# MINI51XAE_v1 register map
File version: 1.0
MINI51XAE_v1 SVD file
Registers are 32-bit, read-write, reset 0x0 unless marked. A register's access mark holds for its fields unless they carry their own. Offsets are from the block's base; lines under a group give offsets from that group; [hi:lo] are bit positions; {n}, {i} and the like mark numbered series; 'fields as' and 'values as' point back to an identical list; <NAME> marks a mode.

## Memory map
0x40004000 WDT size 0x4 — WDT Register Map
0x40010000 TMR blocks up to offset 0x50 — TMR Register Map
0x40020000 I2C blocks up to offset 0x44 — I2C Register Map
0x40030000 SPI blocks up to offset 0x48 — SPI Register Map
0x40040000 PWM blocks up to offset 0x88 — PWM Register Map
0x40050000 UART0 size 0x34 — UART Register Map
0x400D0000 ACMP size 0x10 — ACMP Register Map
0x400E0000 ADC blocks up to offset 0x58 — ADC Register Map
0x40150000 UART1 size 0x34 — UART Register Map
0x50000000 SYS blocks up to offset 0x104 — SYS Register Map
0x50000200 CLK blocks up to offset 0x28 — CLK Register Map
0x50000300 INT blocks up to offset 0x88 — INT Register Map
0x50004000 GP blocks up to offset 0x2B8 — GPIO Register Map
0x5000C000 FMC blocks up to offset 0x44 — FMC Register Map
0x50014000 HDIV size 0x14 — HDIV Register Map
0xE000E000 SCS blocks up to offset 0xD24 — SCS Register Map

## INT — INT Register Map
Base 0x50000300
{0x0+4i} IRQ{i}SRC ro reset not defined (i=0..9) — IRQ{i} (BOD) Interrupt Source Identity
  [2:0] INT_SRC — Interrupt Source
{0x0+4i} IRQ{i}SRC ro reset not defined (i=12..14) — IRQ{i} (BOD) Interrupt Source Identity
  [2:0] INT_SRC — Interrupt Source
{0x0+4i} IRQ{i}SRC ro reset not defined (i=16..18) — IRQ{i} (BOD) Interrupt Source Identity
  [2:0] INT_SRC — Interrupt Source
0x64 IRQ25SRC ro reset not defined — IRQ25 (BOD) Interrupt Source Identity
  [2:0] INT_SRC — Interrupt Source
0x70 IRQ28SRC ro reset not defined — IRQ28 (BOD) Interrupt Source Identity
  [2:0] INT_SRC — Interrupt Source
0x74 IRQ29SRC ro reset not defined — IRQ29 (BOD) Interrupt Source Identity
  [2:0] INT_SRC — Interrupt Source
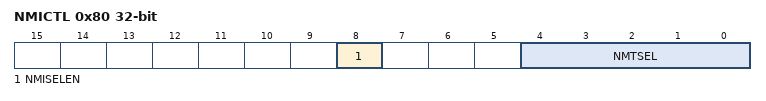
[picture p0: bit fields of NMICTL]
0x80 NMICTL — NMI Source Interrupt Select Control Register
  [8] NMISELEN — NMI Interrupt Enable Control (Write Protected). Note: This bit is the protected bit, and programming it needs to write 0x59, 0x16, and 0x88 to address 0x5000_0100 to disable register protection. Refer to the register REGWRPROT at address SYS_BA+0x100.
    0=NMI interrupt Disabled; 1=NMI interrupt Enabled
  [4:0] NMTSEL — NMI Interrupt Source Selection. The NMI interrupt to Cortex-M0 can be selected from one of the peripheral interrupt by setting NMTSEL.
0x84 IRQSTS — MCU IRQ Number Identity Register
  [31:0] IRQ — MCU IRQ Source Register. The IRQ collects all the interrupts from the peripherals and generates the synchronous interrupt to Cortex-M0 core. There are two modes to generate interrupt to Cortex-M0 - the normal mode and test mode. The IRQ collects all interrupts from each peripheral and synchronizes them then interrupts the Cortex-M0. When the IRQ[n] is 0, setting IRQ[n] to 1 will generate an interrupt to Cortex-M0 NVIC[n]. When the IRQ[n] is 1 (mean an interrupt is assert), setting 1 to the MCU_bit[n] will clear the interrupt and setting IRQ[n] 0 has no effect.

## HDIV — HDIV Register Map
Base 0x50014000
0x00 HDIV_DIVIDEND — Dividend Source Register
  [31:0] DIVIDEND — Dividend Source. This register is given the dividend of divider before calculation starting.
0x04 HDIV_DIVISOR reset 0xFFFF — Divisor Source Resister
  [15:0] DIVISOR — Divisor Source. This register is given the divisor of divider before calculation starts. Note: When this register is written, hardware divider will start calculate.
0x08 HDIV_QUOTIENT — Quotient Result Resister
  [31:0] QUOTIENT — Quotient Result. This register holds the quotient result of divider after calculation complete.
0x0C HDIV_REM — Remainder Result Register
  [31:0] REM — Remainder Result. The remainder of hardware divider is 16-bit sign integer (REM[15:0]) with sign extension (REM[31:16]) to 32-bit integer.
0x10 HDIV_STATUS ro reset 0x1 — Divider Status Register
  [1] DIVBYZERO — Divisor Zero Warning. Note: The DIVBYZERO flag is used to indicate divide-by-zero situation and updated whenever HDIV_DIVISOR is written. This register is read only.
    0=The divisor is not 0; 1=The divisor is 0
